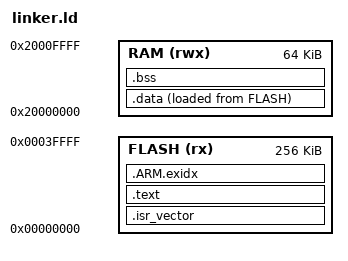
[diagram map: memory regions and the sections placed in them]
ENTRY(Reset_Handler)

MEMORY
{
    FLASH (rx)  : ORIGIN = 0x00000000, LENGTH = 256K
    RAM   (rwx) : ORIGIN = 0x20000000, LENGTH = 64K
}

__StackTop = ORIGIN(RAM) + LENGTH(RAM);
__StackLimit = __StackTop - 4K;

SECTIONS
{
    .isr_vector :
    {
        KEEP(*(.isr_vector))
    } > FLASH

    .text :
    {
        *(.text*)
        *(.rodata*)
        KEEP(*(.init))
        KEEP(*(.fini))
        . = ALIGN(4);
    } > FLASH

    .ARM.exidx :
    {
        *(.ARM.exidx*)
    } > FLASH

    .data :
    {
        . = ALIGN(4);
        _sdata = .;
        *(.data*)
        . = ALIGN(4);
        _edata = .;
    } > RAM AT > FLASH

    _sidata = LOADADDR(.data);

    .bss (NOLOAD) :
    {
        . = ALIGN(4);
        _sbss = .;
        *(.bss*)
        *(COMMON)
        . = ALIGN(4);
        _ebss = .;
    } > RAM

    . = ALIGN(8);
    _end = .;

    ASSERT(_end <= __StackLimit, "RAM overlaps reserved main stack")
}
